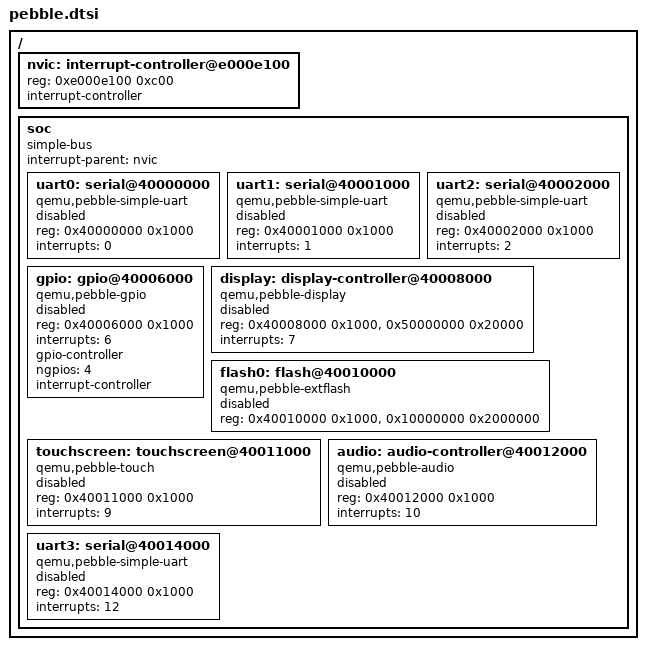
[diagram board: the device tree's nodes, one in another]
// SPDX-FileCopyrightText: 2026 Core Devices LLC
// SPDX-License-Identifier: (GPL-2.0-only OR BSD-2-Clause)

#include <dt-bindings/gpio/gpio.h>

/ {
	#address-cells = <1>;
	#size-cells = <1>;

	nvic: interrupt-controller@e000e100 {
		reg = <0xe000e100 0xc00>;
		interrupt-controller;
		#interrupt-cells = <1>;
		#address-cells = <0>;
	};

	soc {
		compatible = "simple-bus";
		#address-cells = <1>;
		#size-cells = <1>;
		interrupt-parent = <&nvic>;
		ranges;

		uart0: serial@40000000 {
			compatible = "qemu,pebble-simple-uart";
			reg = <0x40000000 0x1000>;
			interrupts = <0>;
			status = "disabled";
		};

		uart1: serial@40001000 {
			compatible = "qemu,pebble-simple-uart";
			reg = <0x40001000 0x1000>;
			interrupts = <1>;
			status = "disabled";
		};

		uart2: serial@40002000 {
			compatible = "qemu,pebble-simple-uart";
			reg = <0x40002000 0x1000>;
			interrupts = <2>;
			status = "disabled";
		};

		gpio: gpio@40006000 {
			compatible = "qemu,pebble-gpio";
			reg = <0x40006000 0x1000>;
			interrupts = <6>;
			gpio-controller;
			#gpio-cells = <2>;
			ngpios = <4>;
			interrupt-controller;
			#interrupt-cells = <2>;
			status = "disabled";
		};

		display: display-controller@40008000 {
			compatible = "qemu,pebble-display";
			reg = <0x40008000 0x1000>, <0x50000000 0x20000>;
			reg-names = "regs", "fb";
			interrupts = <7>;
			status = "disabled";
		};

		flash0: flash@40010000 {
			compatible = "qemu,pebble-extflash";
			reg = <0x40010000 0x1000>, <0x10000000 0x2000000>;
			reg-names = "regs", "mem";
			status = "disabled";
		};

		touchscreen: touchscreen@40011000 {
			compatible = "qemu,pebble-touch";
			reg = <0x40011000 0x1000>;
			interrupts = <9>;
			status = "disabled";
		};

		audio: audio-controller@40012000 {
			compatible = "qemu,pebble-audio";
			reg = <0x40012000 0x1000>;
			interrupts = <10>;
			#sound-dai-cells = <0>;
			status = "disabled";
		};

		uart3: serial@40014000 {
			compatible = "qemu,pebble-simple-uart";
			reg = <0x40014000 0x1000>;
			interrupts = <12>;
			status = "disabled";
		};
	};
};
